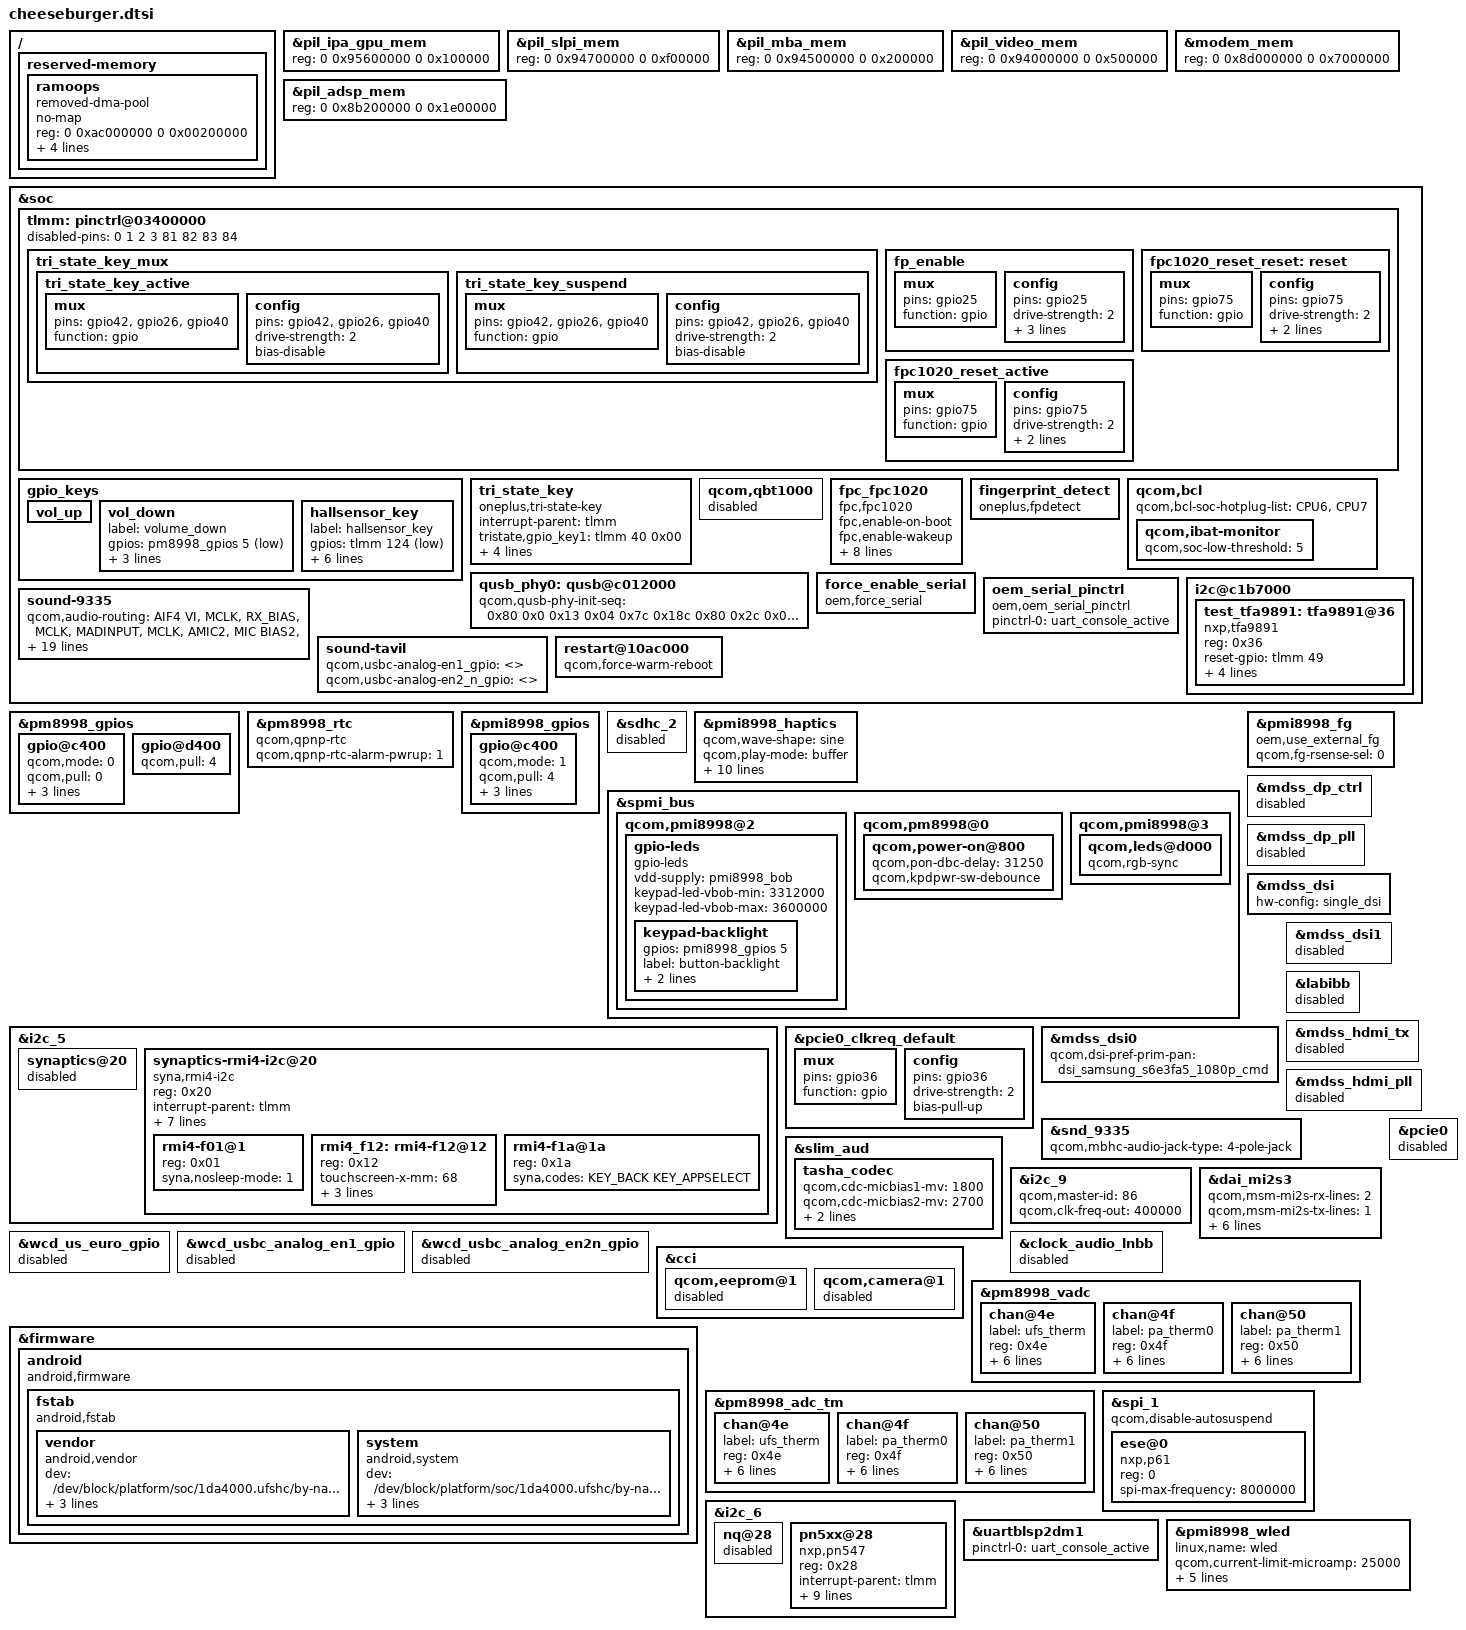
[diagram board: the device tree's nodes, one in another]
/* Copyright (c) 2016-2017, The Linux Foundation. All rights reserved.
 *
 * This program is free software; you can redistribute it and/or modify
 * it under the terms of the GNU General Public License version 2 and
 * only version 2 as published by the Free Software Foundation.
 *
 * This program is distributed in the hope that it will be useful,
 * but WITHOUT ANY WARRANTY; without even the implied warranty of
 * MERCHANTABILITY or FITNESS FOR A PARTICULAR PURPOSE.  See the
 * GNU General Public License for more details.
 */

#include <dt-bindings/input/input.h>

#include "pxlw-iris-settings.dtsi"

/* Include thermal */
#include "msm8998-oneplus-common-thermal.dtsi"

/* Disable SMP2P Remote Debug for production */
#include "msm-rdbg-disable.dtsi"

/ {
	reserved-memory {
		ramoops {
			compatible = "removed-dma-pool", "ramoops";
			no-map;
			reg = <0 0xac000000 0 0x00200000>;
			record-size = <0x10000>;
			console-size = <0x60000>;
			ftrace-size = <0x10000>;
			pmsg-size = <0x20000>;
			status = "okay";
		};
	};
};

&pil_ipa_gpu_mem{
    reg = <0 0x95600000 0 0x100000>;//move start address +4M to match modem aligned
};

&pil_slpi_mem{
    reg = <0 0x94700000 0 0xf00000>;//move start address +4M to match modem aligned
};

&pil_mba_mem{
    reg = <0 0x94500000 0 0x200000>;//move start address +4M to match modem aligned
};

&pil_video_mem{
    reg = <0 0x94000000 0 0x500000>;//move start address +4M to match modem aligned
};

&modem_mem{
    reg = <0 0x8d000000 0 0x7000000>;//move start address +4M to match modem aligned
};

&pil_adsp_mem{
    reg = <0 0x8b200000 0 0x1e00000>; //increae 4M size by oneplus
};

/* I/O */
&soc {
	pinctrl@03400000 {
		disabled-pins = <0 1 2 3 81 82 83 84>;
	};

	gpio_keys {
		vol_up {
			/delete-property/ gpio-key,wakeup;
		};
		vol_down {
			label = "volume_down";
			gpios = <&pm8998_gpios 5 0x1>;
			linux,input-type = <1>;
			linux,code = <114>;
			debounce-interval = <15>;
		};
		hallsensor_key {
			label = "hallsensor_key";
			gpios = <&tlmm 124 1>;
			interrupt-parent = <&tlmm>;
			interrupts = <124 0x0>;
			linux,input-type = <5>;
			linux,code = <0>;
			gpio-key,wakeup;
			debounce-interval = <15>;
		};
	};

	tlmm: pinctrl@03400000 {
		tri_state_key_mux {
			tri_state_key_active: tri_state_key_active {
				mux {
					pins = "gpio42","gpio26","gpio40";
					function = "gpio";
				};

				config {
					pins = "gpio42","gpio26","gpio40";
					drive-strength = <2>;
					bias-disable;
				};
			};

			tri_state_key_suspend: tri_state_key_suspend {
				mux {
					pins = "gpio42","gpio26","gpio40";
					function = "gpio";
				};

				config {
					pins = "gpio42","gpio26","gpio40";
					drive-strength = <2>;
					bias-disable;
				};
			};
		};
	};

	/* Tri-state key */
	tri_state_key {
		compatible = "oneplus,tri-state-key";
		status = "okay";
		interrupt-parent = <&tlmm>;
		tristate,gpio_key1 = <&tlmm 40 0x00>;
		tristate,gpio_key2 = <&tlmm 42 0x00>;
		tristate,gpio_key3 = <&tlmm 26 0x00>;
		pinctrl-names = "pmx_tri_state_key_active", "pmx_tri_state_key_suspend";
		pinctrl-0 = <&tri_state_key_active>;
		pinctrl-1 = <&tri_state_key_suspend>;
	};

	qcom,qbt1000 {
        status = "disabled";
	};

	/* Fingerprint */
	fpc_fpc1020 {
		compatible = "fpc,fpc1020";
		fpc,enable-on-boot;
		fpc,enable-wakeup;
		interrupt-parent = <&tlmm>;
		interrupts = <121 0x0>;
		fpc,irq-gpio    = <&tlmm 121 0x0>;
		fpc,enable-gpio = <&tlmm 25 0x0>;
		vdd_ana-supply  = <&pm8998_l6>;

		pinctrl-names = "fpc1020_reset_reset",
				"fpc1020_reset_active",
				"fp_enable";

		pinctrl-0 = <&fpc1020_reset_reset>;
		pinctrl-1 = <&fpc1020_reset_active>;
		pinctrl-2 = <&fp_enable>;
	};

	fingerprint_detect {
		compatible = "oneplus,fpdetect";
	};

	tlmm: pinctrl@03400000 {
		fp_enable: fp_enable {
			mux {
				pins = "gpio25";
				function = "gpio";
			};

			config {
				pins = "gpio25";
				drive-strength = <2>;
				bias-pull-up;
				output-enable;
				output-high;
			};
		};

		/* GPIO_40 : FP_RESET_N */
		fpc1020_reset_reset: reset {
			mux {
				pins = "gpio75";
				function = "gpio";
			};

			config {
				pins = "gpio75";
				drive-strength = <2>;
				bias-disable;
				output-low;
			};
		};

		/* GPIO_40 : FP_RESET_N, state device active */
		fpc1020_reset_active: fpc1020_reset_active {
			mux {
				pins = "gpio75";
				function = "gpio";
			};

			config {
				pins = "gpio75";
				drive-strength = <2>;
				bias-disable;
				output-high;
			};
		};
	};

	qcom,bcl {
		qcom,bcl-soc-hotplug-list = <&CPU6 &CPU7>;
		qcom,ibat-monitor {
			qcom,soc-low-threshold = <5>;
		};
	};

	/* Add  0x9c 0x21C, 0xf0 0x23C */
	qusb_phy0: qusb@c012000 {
	qcom,qusb-phy-init-seq =
			/* <value reg_offset> */
				<0x80 0x0
				0x13 0x04
				0x7c 0x18c
				0x80 0x2c
				0x0a 0x184
				0x9c 0x21C
				0xf0 0x23C
				0x0f 0x240>;
	};
	force_enable_serial {
		compatible = "oem,force_serial";
	};
	oem_serial_pinctrl {
		compatible = "oem,oem_serial_pinctrl";
		pinctrl-names = "uart_pinctrl_active";
		pinctrl-0 = <&uart_console_active>;
	};
};

&pm8998_gpios {
	/* GPIO 5 for Vol- Key */
	gpio@c400 {
		status = "okay";
		qcom,mode = <0>;
		qcom,pull = <0>;
		qcom,vin-sel = <0>;
		qcom,src-sel = <0>;
		qcom,out-strength = <1>;
	};
};

&pm8998_rtc {
	compatible = "qcom,qpnp-rtc";
	qcom,qpnp-rtc-alarm-pwrup = <1>;
};

&pmi8998_gpios {
	/* button-backlight */
	gpio@c400 {
		qcom,mode = <1>;		/* Output */
		qcom,pull = <4>;		/* Pull Down*/
		qcom,master-en = <1>;		/* Enable GPIO */
		qcom,invert = <1>;
		qcom,out-strength = <1>;
		status = "okay";
	};
};

&sdhc_2 {
	status = "disabled";
};

&pmi8998_haptics {
	status = "okay";
	qcom,wave-shape = "sine";
	qcom,play-mode = "buffer";
	qcom,wave-samples = <0x28 0x28 0x28 0x28 0x28 0x28 0x28 0x28>;
	qcom,brake-pattern = <0x3 0x3 0x3 0x3>;
	qcom,wave-rep-cnt = <1>;
	qcom,wave-samp-rep-cnt = <1>;
	qcom,use-play-irq;
	qcom,vmax-mv = <2088>;
	qcom,wave-play-rate-us = <4255>;
	qcom,lra-auto-res-mode = "qwd";
	qcom,lra-res-cal-period = <32>;
};

&spmi_bus {
	qcom,pmi8998@2 {
		/* button-backlight */
		gpio-leds {
			compatible = "gpio-leds";
			status = "okay";
			vdd-supply = <&pmi8998_bob>;
			keypad-led-vbob-min = <3312000>;
			keypad-led-vbob-max = <3600000>;
			keypad-backlight {
				gpios = <&pmi8998_gpios 5 0>; //here maybe pm8998_gpios, depends on what you use.
				label = "button-backlight";
				linux,default-trigger = "none";
				default-state = "off";
			};
		};
	};

	/*shankai@bsp, add debounce time 2017-3-18*/
	qcom,pm8998@0{
		qcom,power-on@800 {
		    qcom,pon-dbc-delay = <31250>;
		    qcom,kpdpwr-sw-debounce;
	    };
	};
	qcom,pmi8998@3 {
		qcom,leds@d000 {
			qcom,rgb-sync;
		};
	};
};

&pmi8998_fg {
	oem,use_external_fg;
	qcom,fg-rsense-sel = <0>;
};


/* Display */
&i2c_5 {
	synaptics@20 {
		status = "disabled";
	};

	synaptics-rmi4-i2c@20 {
		compatible = "syna,rmi4-i2c";
		reg = <0x20>;
		#address-cells = <1>;
		#size-cells = <0>;
		interrupt-parent = <&tlmm>;
		interrupts = <125 IRQ_TYPE_EDGE_FALLING>;
		pinctrl-names = "default", "sleep";
		pinctrl-0 = <&ts_active>;
		pinctrl-1 = <&ts_int_suspend &ts_reset_suspend>;
		vdd-supply = <&pm8998_l28>;
		vio-supply = <&pm8998_l6>;
		syna,reset-delay-ms = <200>;
		syna,startup-delay-ms = <200>;

		rmi4-f01@1 {
			reg = <0x01>;
			syna,nosleep-mode = <1>;
		};

		rmi4_f12: rmi4-f12@12 {
			reg = <0x12>;
			touchscreen-x-mm = <68>;
			touchscreen-y-mm = <122>;
			syna,sensor-type = <1>;
			syna,rezero-wait-ms = <200>;
		};

		rmi4-f1a@1a {
			reg = <0x1a>;
			syna,codes = <KEY_BACK KEY_APPSELECT>;
		};
	};
};

&pcie0_clkreq_default {
	mux {
		pins = "gpio36";
		function = "gpio";
	};

	config {
		pins = "gpio36";
		drive-strength = <2>;
		bias-pull-up;
	};
};

&mdss_dp_ctrl {
	status = "disabled";
};

&mdss_dp_pll {
	status = "disabled";
};

&mdss_dsi {
	hw-config = "single_dsi";
};

&mdss_dsi0 {
        qcom,dsi-pref-prim-pan = <&dsi_samsung_s6e3fa5_1080p_cmd>;
};

&mdss_dsi1 {
	status = "disabled";
	/delete-property/ qcom,dsi-pref-prim-pan;
};

&labibb {
	status = "disabled";
};

&mdss_hdmi_tx {
	status = "disabled";
};

&mdss_hdmi_pll {
	status = "disabled";
};

&snd_9335 {
	qcom,mbhc-audio-jack-type = "4-pole-jack";
};
/*
 * liuhaituo@MultiMediaAudio modified for adapation phone
 * headset and AKG headset-mic 2018/4/26
 */
&slim_aud {
	tasha_codec {
		qcom,cdc-micbias1-mv = <1800>;
		qcom,cdc-micbias2-mv = <2700>;
		qcom,cdc-micbias3-mv = <1800>;
		qcom,cdc-micbias4-mv = <1800>;
	};
};

/* Audio */
&soc {
	i2c@c1b7000 {
		status = "ok";
		test_tfa9891: tfa9891@36 {
			compatible = "nxp,tfa9891";
			reg = <0x36>;
			reset-gpio= <&tlmm 49 0>;
			irq-gpio= <&tlmm 50 0>;
			bob_power-supply = <&pmi8998_bob>;
			qcom,bob_power-voltage-level = <2950000 2960000>;
			qcom,bob_power-current-level = <200 800000>;
			status = "ok";
		};
	};

	sound-9335 {
		qcom,audio-routing =
			"AIF4 VI", "MCLK",
			"RX_BIAS", "MCLK",
			"MADINPUT", "MCLK",
			"AMIC2", "MIC BIAS2",
			"MIC BIAS2", "Headset Mic",
			"AMIC3", "MIC BIAS2",
			"MIC BIAS2", "ANCRight Headset Mic",
			"AMIC4", "MIC BIAS2",
			"MIC BIAS2", "ANCLeft Headset Mic",
			"AMIC5", "MIC BIAS3",
			"MIC BIAS3", "Handset Mic",
			"AMIC6", "MIC BIAS4",
			"MIC BIAS4", "Analog Mic6",
			"DMIC0", "MIC BIAS1",
			"MIC BIAS1", "Digital Mic0",
			"DMIC1", "MIC BIAS1",
			"MIC BIAS1", "Digital Mic1",
			"DMIC2", "MIC BIAS4",
			"MIC BIAS4", "Digital Mic2",
			"DMIC3", "MIC BIAS4",
			"MIC BIAS4", "Digital Mic3",
			"DMIC4", "MIC BIAS3",
			"MIC BIAS3", "Digital Mic4",
			"DMIC5", "MIC BIAS3",
			"MIC BIAS3", "Digital Mic5",
			"SpkrLeft IN", "SPK1 OUT",
			"SpkrRight IN", "SPK2 OUT";
		qcom,us-euro-gpios = <>;
		qcom,msm-mbhc-hphl-swh = <1>;
		qcom,msm-mbhc-gnd-swh = <1>;
		qcom,wsa-max-devs = <>;
		qcom,wsa-devs = <>;
		qcom,wsa-aux-dev-prefix = <>;
	};

	sound-tavil {
		qcom,usbc-analog-en1_gpio = <>;
		qcom,usbc-analog-en2_n_gpio = <>;
	};
};

&i2c_9 { /* BLSP2 QUP9 for Audio Speaker */
	qcom,master-id = <86>;
	qcom,clk-freq-out = <400000>;
	status = "ok";
};

&dai_mi2s3 {
	qcom,msm-mi2s-rx-lines = <2>;
	qcom,msm-mi2s-tx-lines = <1>;
	qcom,msm-mi2s-slave = <0>;
	qcom,msm-mi2s-ext-mclk = <0>;
	pinctrl-names = "default", "sleep";
	pinctrl-0 = <&quat_mi2s_active
			&quat_mi2s_sd0_active
			&quat_mi2s_sd1_active>;
	pinctrl-1 = <&quat_mi2s_sleep
			&quat_mi2s_sd0_sleep
			&quat_mi2s_sd1_sleep>;
};

&wcd_us_euro_gpio {
	status = "disabled";
};

&wcd_usbc_analog_en1_gpio {
	status = "disabled";
};

&wcd_usbc_analog_en2n_gpio {
	status = "disabled";
};
&clock_audio_lnbb {
	status = "disabled";
};

/* Camera */
&cci {
	qcom,eeprom@1 {
		status = "disabled";
	};

	qcom,camera@1 {
		status = "disabled";
	};
};

&firmware {
	android {
		compatible = "android,firmware";
		fstab {
			compatible = "android,fstab";
			vendor {
				compatible = "android,vendor";
				dev = "/dev/block/platform/soc/1da4000.ufshc/by-name/vendor";
				type = "ext4";
				mnt_flags = "ro,barrier=1,discard";
				fsmgr_flags = "wait";
				status = "ok";
			};
			system {
				compatible = "android,system";
				dev = "/dev/block/platform/soc/1da4000.ufshc/by-name/system";
				type = "ext4";
				mnt_flags = "ro,barrier=1,discard";
				fsmgr_flags = "wait";
				status = "ok";
			};
		};
	};
};

/*Anderson-Config_UARTPIN_as_GPIO*]**/

/* External Thermistors */
&pm8998_vadc {
	#thermal-sensor-cells = <1>;
	chan@4e {
		label = "ufs_therm";
		reg = <0x4e>;
		qcom,decimation = <2>;
		qcom,pre-div-channel-scaling = <0>;
		qcom,calibration-type = "ratiometric";
		qcom,scale-function = <2>;
		qcom,hw-settle-time = <2>;
		qcom,fast-avg-setup = <0>;
	};

	chan@4f {
		label = "pa_therm0";
		reg = <0x4f>;
		qcom,decimation = <2>;
		qcom,pre-div-channel-scaling = <0>;
		qcom,calibration-type = "ratiometric";
		qcom,scale-function = <2>;
		qcom,hw-settle-time = <2>;
		qcom,fast-avg-setup = <0>;
	};

	chan@50 {
		label = "pa_therm1";
		reg = <0x50>;
		qcom,decimation = <2>;
		qcom,pre-div-channel-scaling = <0>;
		qcom,calibration-type = "ratiometric";
		qcom,scale-function = <2>;
		qcom,hw-settle-time = <2>;
		qcom,fast-avg-setup = <0>;
	};
};

&pm8998_adc_tm {
	chan@4e {
		label = "ufs_therm";
		reg = <0x4e>;
		qcom,pre-div-channel-scaling = <0>;
		qcom,calibration-type = "ratiometric";
		qcom,scale-function = <2>;
		qcom,hw-settle-time = <2>;
		qcom,btm-channel-number = <0x80>;
		qcom,thermal-node;
	};

	chan@4f {
		label = "pa_therm0";
		reg = <0x4f>;
		qcom,pre-div-channel-scaling = <0>;
		qcom,calibration-type = "ratiometric";
		qcom,scale-function = <2>;
		qcom,hw-settle-time = <2>;
		qcom,btm-channel-number = <0x88>;
		qcom,thermal-node;
	};

	chan@50 {
		label = "pa_therm1";
		reg = <0x50>;
		qcom,pre-div-channel-scaling = <0>;
		qcom,calibration-type = "ratiometric";
		qcom,scale-function = <2>;
		qcom,hw-settle-time = <2>;
		qcom,btm-channel-number = <0x90>;
		qcom,thermal-node;
	};
};


/*pcie 0 don't used,gpio 37 will used in nfc.*/
/*but gpio37 will request in pcie0. so disable it*/
&pcie0 {
	status = "disabled";
};

&pm8998_gpios {
	gpio@d400 {
		qcom,pull = <4>;
	};
};

&spi_1 {
	status = "ok";
	qcom,disable-autosuspend;

	ese@0 {
		compatible = "nxp,p61";
		reg = <0>;
		spi-max-frequency = <8000000>;
	};
};

&i2c_6 { /* BLSP1 QUP6 (NFC) */
	nq@28 {
		status = "disabled";
	};

	pn5xx@28 {
		compatible = "nxp,pn547";
		reg = <0x28>;
		interrupt-parent = <&tlmm>;
		interrupts = <92 0x1>;
		nxp,irq_gpio = <&tlmm 92 0x00>;
		nxp,dwld_en = <&tlmm 93 0x00>;
		nxp,ven = <&tlmm 12 0x01>;
		qcom,clk-src = "BBCLK3";
		qcom,clk-gpio = <&pm8998_gpios 21 0x00>;
		clocks = <&clock_rpmcc RPM_SMD_LN_BB_CLK3_PIN>;
		clock-names = "nfc_clk";
		pinctrl-names = "nfc_active", "nfc_suspend";
		pinctrl-0 = <&nfc_int_active &nfc_enable_active>;
		pinctrl-1 = <&nfc_int_suspend &nfc_enable_suspend>;
	};
};

&uartblsp2dm1 {
	pinctrl-names = "uart_active";
	pinctrl-0 = <&uart_console_active>;
	status = "okay";
};

&soc {
	restart@10ac000 {
		qcom,force-warm-reboot;
	};
};

&pmi8998_wled {
        linux,name = "wled";
        qcom,current-limit-microamp = <25000>;
        somc,init-br-ua = <10000>;
        somc-s1,br-power-save-ua = <800>;
        somc,bl-scale-enabled;
        somc,area_count_table_size = <0>;
        qcom,enabled-strings = <0 1 2>;
};
